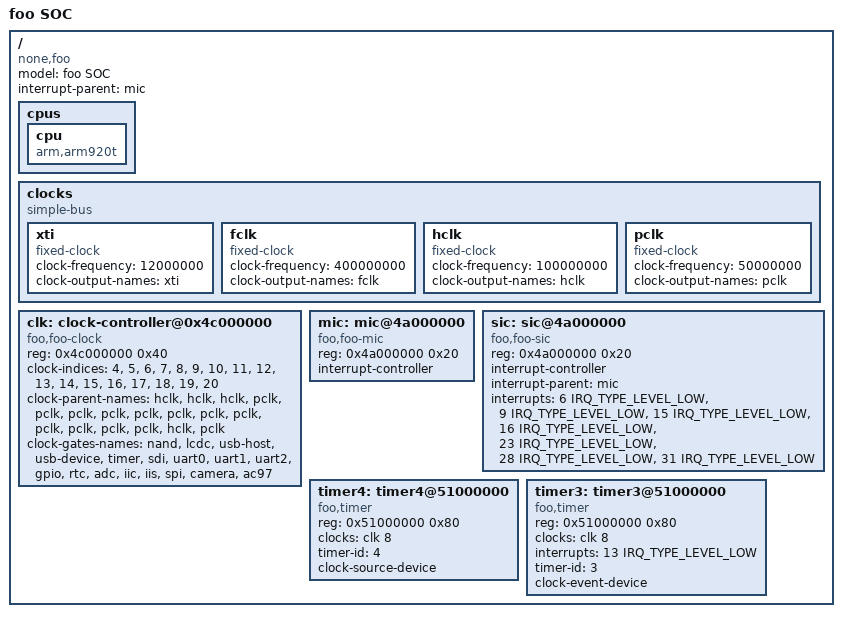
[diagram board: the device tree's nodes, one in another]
#include "skeleton.dtsi"

#include <dt-bindings/gpio/gpio.h>
#include <dt-bindings/interrupt-controller/irq.h>

/ {
	model = "foo SOC";
	compatible = "none,foo";
	interrupt-parent = <&mic>;

	cpus {
		#address-cells = <0>;
		#size-cells = <0>;

		cpu {
			compatible = "arm,arm920t";
		};
	};

	clocks {
		compatible = "simple-bus";
		#address-cells = <1>;
		#size-cells = <1>;

		xti: xti {
			compatible = "fixed-clock";
			clock-frequency = <12000000>;
			clock-output-names = "xti";
			#clock-cells = <0>;
		};

		fclk: fclk {
			compatible = "fixed-clock";
			clock-frequency = <400000000>;
			clock-output-names = "fclk";
			#clock-cells = <0>;
		};

		hclk: hclk {
			compatible = "fixed-clock";
			clock-frequency = <100000000>;
			clock-output-names = "hclk";
			#clock-cells = <0>;
		};

		pclk: pclk {
			compatible = "fixed-clock";
			clock-frequency = <50000000>;
			clock-output-names = "pclk";
			#clock-cells = <0>;
		};
	};

	clk: clock-controller@0x4c000000 {
		compatible = "foo,foo-clock";
		reg = <0x4c000000 0x40>;
		#clock-cells = <1>;

		clock-indices = <4>, <5>, <6>, <7>, 
				<8>, <9>, <10>,<11>,
				<12>, <13>, <14>, <15>,
				<16>, <17>, <18>, <19>,
				<20>;
		clock-parent-names = "hclk","hclk","hclk","pclk",
				     "pclk","pclk","pclk","pclk",
				     "pclk","pclk","pclk","pclk",
				     "pclk","pclk","pclk","hclk",
				     "pclk";
		clock-gates-names = "nand", "lcdc", "usb-host", "usb-device",
				    "timer", "sdi", "uart0", "uart1",
				    "uart2", "gpio", "rtc", "adc",
				    "iic", "iis", "spi", "camera",
				    "ac97";
	};

	mic: mic@4a000000 {
		compatible = "foo,foo-mic";
		reg = <0x4a000000 0x20>;
		interrupt-controller;
		#interrupt-cells = <2>;
	};

	sic: sic@4a000000 {
		compatible = "foo,foo-sic";
		reg = <0x4a000000 0x20>;
		interrupt-controller;
		#interrupt-cells = <2>;

		interrupt-parent = <&mic>;
		interrupts = <6 IRQ_TYPE_LEVEL_LOW>,
			     <9 IRQ_TYPE_LEVEL_LOW>,
			     <15 IRQ_TYPE_LEVEL_LOW>,
			     <16 IRQ_TYPE_LEVEL_LOW>,
			     <23 IRQ_TYPE_LEVEL_LOW>,
			     <28 IRQ_TYPE_LEVEL_LOW>,
			     <31 IRQ_TYPE_LEVEL_LOW>;
	};

	timer4: timer4@51000000 {
		compatible = "foo,timer";
		reg = <0x51000000 0x80>;
		clocks = <&clk 8>;
		timer-id = <4>;
		clock-source-device;
	};

	timer3: timer3@51000000 {
		compatible = "foo,timer";
		reg = <0x51000000 0x80>;
		clocks = <&clk 8>;
		interrupts = <13 IRQ_TYPE_LEVEL_LOW>;
		timer-id = <3>;
		clock-event-device;
	};
};
